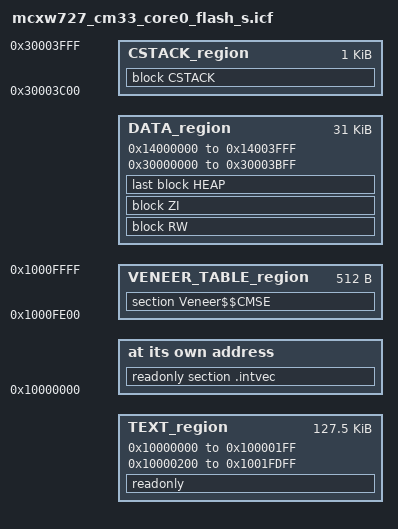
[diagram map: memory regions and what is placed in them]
/*
** ###################################################################
**     Processors:          MCXW727AMFTA_cm33_core0
**                          MCXW727CMFTA_cm33_core0
**                          MCXW727DMFTA_cm33_core0
**
**     Compiler:            IAR ANSI C/C++ Compiler for ARM
**     Reference manual:    Rev. 6, 05/22/2022
**     Version:             rev. 1.0, 2023-05-20
**     Build:               b240719
**
**     Abstract:
**         Linker file for the IAR ANSI C/C++ Compiler for ARM
**
**     Copyright 2016 Freescale Semiconductor, Inc.
**     Copyright 2016-2024 NXP
**     SPDX-License-Identifier: BSD-3-Clause
**
**     http:                 www.nxp.com
**     mail:                 support@nxp.com
**
** ###################################################################
*/


/* Stack and Heap Sizes */
if (isdefinedsymbol(__stack_size__)) {
  define symbol __size_cstack__        = __stack_size__;
} else {
  define symbol __size_cstack__        = 0x0400;
}

if (isdefinedsymbol(__heap_size__)) {
  define symbol __size_heap__          = __heap_size__;
} else {
  define symbol __size_heap__          = 0x0400;
}

/* Only the first 64kB of flash is used as secure memory. */
define symbol m_interrupts_start               = 0x10000000;
define symbol m_interrupts_end                 = 0x100001FF;

define symbol m_text_start                     = 0x10000200;
define symbol m_text_end                       = 0x1001FDFF;

/* Only first 32kB of data RAM is used as secure memory(16K TCM-CODE + 16K TCM-SYS). */
define symbol m_data0_start                     = 0x14000000;
define symbol m_data0_end                       = 0x14003FFF;

define symbol m_data1_start                     = 0x30000000;
define symbol m_data1_end                       = 0x30003FFF - __size_cstack__;

define symbol m_stack_start                    = 0x30004000 - __size_cstack__;
define symbol m_stack_end                      = 0x30003FFF;

/* 512B - memory for veneer table (NSC - secure, non-secure callable memory) */
define symbol m_veneer_table_start             = 0x1000FE00;
define symbol m_veneer_table_size              = 0x200;

define memory mem with size = 4G;

define region TEXT_region             = mem:[from m_interrupts_start to m_interrupts_end]
                                      | mem:[from m_text_start to m_text_end];
define region DATA_region             = mem:[from m_data0_start to m_data0_end]
                                      | mem:[from m_data1_start to m_data1_end];
define region CSTACK_region           = mem:[from m_stack_start to m_stack_end];

define region VENEER_TABLE_region       = mem:[from m_veneer_table_start to m_veneer_table_start + m_veneer_table_size - 1];


define block CSTACK    with alignment = 8, size = __size_cstack__   { };
define block HEAP      with alignment = 8, size = __size_heap__     { };
define block RW        { readwrite };
define block ZI        { zi };

initialize by copy { readwrite, section .textrw };

if (isdefinedsymbol(__USE_DLIB_PERTHREAD))
{
  /* Required in a multi-threaded application */
  initialize by copy with packing = none { section __DLIB_PERTHREAD };
}

do not initialize  { section .noinit };

place at address mem: m_interrupts_start    { readonly section .intvec };
place in TEXT_region                        { readonly };
place in DATA_region                        { block RW };
place in DATA_region                        { block ZI };
place in DATA_region                        { last block HEAP };
place in CSTACK_region                      { block CSTACK };

place in VENEER_TABLE_region                { section Veneer$$CMSE };
